# CY8C4xxx register map
File version: 0.1
Registers are 8-bit, read-write, no defined reset value unless marked. A register's access mark holds for its fields unless they carry their own. Offsets are from the block's base; [hi:lo] are bit positions; {n}, {i} and the like mark numbered series.

## CLK — Programmable clocks
Base 0x40020000
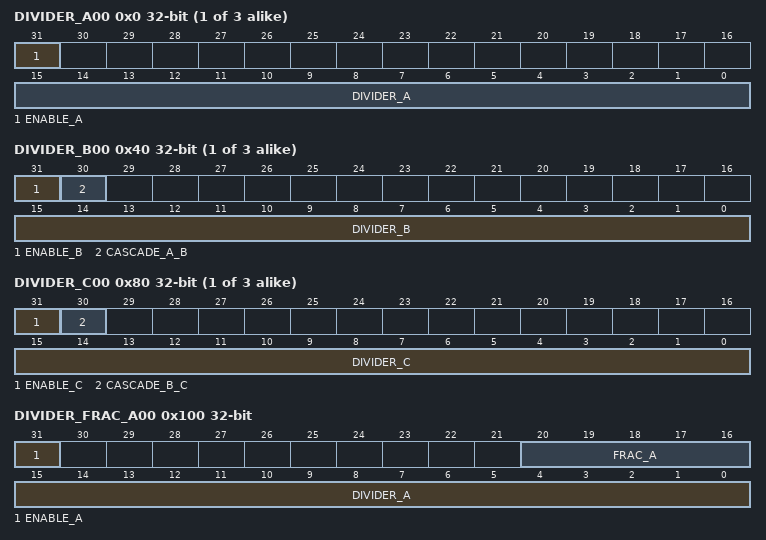
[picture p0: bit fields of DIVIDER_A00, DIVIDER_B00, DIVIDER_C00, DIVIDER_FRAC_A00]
{0x0+4i} DIVIDER_A{i:02} 32-bit (i=0..2) — Clock Divider Configuration
  [31] ENABLE_A — Enable divider A.
  [15:0] DIVIDER_A — Divider value for divider A in the row. OUTPUT= INPUT / (DIVIDER_A+1). In other words, a value of 0 means divide by 1. Note that selecting divide by 1 (value 0) does not work for blocks that require full DIVIDED_CLOCK clock reconstruction (See Section 20.6 in SAS).
{0x40+4i} DIVIDER_B{i:02} 32-bit (i=0..2) — Clock Divider Configuration
  [31] ENABLE_B — Enable divider B.
  [30] CASCADE_A_B — Cascade divider A into divider B
  [15:0] DIVIDER_B — Divider value for divider B in the row. OUTPUT= INPUT / (DIVIDER_B+1). In other words, a value of 0 means divide by 1. Note that selecting divide by 1 (value 0) does not work for blocks that require full DIVIDED_CLOCK clock reconstruction (See Section 20.6 in SAS). Also note that dividide by 1 does not work if CASCADE_A_B=1.
{0x80+4i} DIVIDER_C{i:02} 32-bit (i=0..2) — Clock Divider Configuration
  [31] ENABLE_C — Enable divider C.
  [30] CASCADE_B_C — Cascade divider B into divider C
  [15:0] DIVIDER_C — Divider value for divider C in the row. OUTPUT= INPUT / (DIVIDER_C+1). In other words, a value of 0 means divide by 1. Note that selecting divide by 1 (value 0) does not work for blocks that require full DIVIDED_CLOCK clock reconstruction (See Section 20.6 in SAS). Also note that dividide by 1 does not work if CASCADE_A_B=1.
0x100 DIVIDER_FRAC_A00 32-bit — Frac Divider Configuration
  [31] ENABLE_A — Enable divider A.
  [20:16] FRAC_A — Fractional divider value: 0/32 .. 31/32
  [15:0] DIVIDER_A — Divider value for divider A in the row. OUTPUT= INPUT / (DIVIDER_A+1). In other words, a value of 0 means divide by 1. Note that selecting divide by 1 (value 0) does not work for blocks that require full DIVIDED_CLOCK clock reconstruction (See Section 20.6 in SAS).
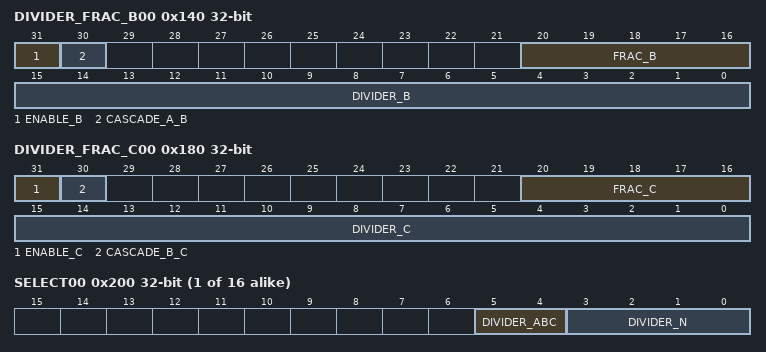
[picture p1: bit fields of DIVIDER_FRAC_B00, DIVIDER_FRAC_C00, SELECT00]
0x140 DIVIDER_FRAC_B00 32-bit — Frac Divider Configuration
  [31] ENABLE_B — Enable divider B.
  [30] CASCADE_A_B — Cascade divider A into divider B
  [20:16] FRAC_B — Fractional divider value: 0/32 .. 31/32
  [15:0] DIVIDER_B — Divider value for divider B in the row. OUTPUT= INPUT / (DIVIDER_B+1). In other words, a value of 0 means divide by 1. Note that selecting divide by 1 (value 0) does not work for blocks that require full DIVIDED_CLOCK clock reconstruction (See Section 20.6 in SAS). Also note that dividide by 1 does not work if CASCADE_A_B=1.
0x180 DIVIDER_FRAC_C00 32-bit — Frac Divider Configuration
  [31] ENABLE_C — Enable divider C.
  [30] CASCADE_B_C — Cascade divider B into divider C
  [20:16] FRAC_C — Fractional divider value: 0/32 .. 31/32
  [15:0] DIVIDER_C — Divider value for divider C in the row. OUTPUT= INPUT / (DIVIDER_C+1). In other words, a value of 0 means divide by 1. Note that selecting divide by 1 (value 0) does not work for blocks that require full DIVIDED_CLOCK clock reconstruction (See Section 20.6 in SAS). Also note that dividide by 1 does not work if CASCADE_A_B=1.
{0x200+4i} SELECT{i:02} 32-bit (i=0..15) — Clock Routing Configuration
  [5:4] DIVIDER_ABC — Select which divider from row to use.
    0=OFF; 1=A; 2=B; 3=C
  [3:0] DIVIDER_N — Select divider bank row to source clock from. ?Addressed as following:?0 to NUMDIV-1: Non-fractional divider?NUMDIV to NUMFRACDIV: Fractional divider?E.g. PSOC4A NUMDIV=3, NUMFRACDIV=1?0 to 2: non-fractional divider 0 to 2?3: fractional divider 0

## PRT0 — GPIO Port Registers
Base 0x40040000
Same registers: PRT1 0x40040100, PRT2 0x40040200, PRT3 0x40040300, PRT4 0x40040400
0x00 DR 32-bit — Port Output Data Register
  [7:0] DATAREG — The data written to this register specifies the high ('1') or low ('0') state for a specific pin. One bit is used for each pin: bit 0 pin 0, bit 1 pin 1, ?, bit 7 for pin 7.
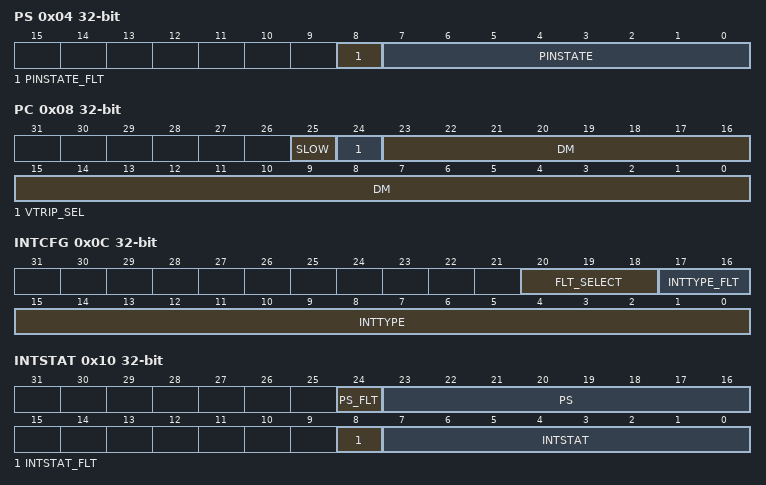
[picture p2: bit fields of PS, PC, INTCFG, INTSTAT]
0x04 PS 32-bit — Port Pin State Register
  [8] PINSTATE_FLT ro — Reads of this register return the logical state of the filtered pin.
  [7:0] PINSTATE ro — Reads of this register return the logical state of the corresponding I/O pin. The data read from this register specifies the logical state of the pin:?1: Reads HIGH if the pin voltage is above the input buffer threshold, logic high.?0: Reads LOW if the pin voltage is below that threshold, logic low.?If the drive mode for the pin is set to high Z Analog, the pin state will read 0 independent of the voltage on the pin.
0x08 PC 32-bit — Port Configuration Register
  [25] SLOW — This bit controls the output edge rate of all pins on the port:?0: fast.?1: slow.
  [24] VTRIP_SEL — The GPIO cells include a VTRIP_SEL signal to alter the input buffer voltage. Note: this bit is ignored for SIO ports, the VTRIP_SEL settings in the SIO register are used instead (a separate VTRIP_SEL is provided for each pin pair).
  [23:0] DM — The GPIO drive mode for a specific pin. Three bits are used for each pin: bits 0, 1 and 2 for pin 0, bits 3, 4 and 5 for pin 1, ?, bits 21, 22 and 23 for pin 7.?Note: when initializing IO's that are connected to a live bus (such as I2C), make sure the IO-Matrix is properly configured (HSIOM_PRT_SELx) before turning the IO on here to avoid producing glitches on the bus.
    0=OFF; 1=INPUT; 2=Cy0_PU; 3=PD_1; 4=Cy0_Z; 5=Z_1; 6=Cy0_1; 7=PD_PU
0x0C INTCFG 32-bit — Port IRQ Configuration Register
  [20:18] FLT_SELECT — Selects which pin is routed through the 50ns glitch filter to provide a glitch-safe interrupt.
  [17:16] INTTYPE_FLT — Same for the glitch filtered pin (selected by FLT_SELECT).
    0=DISABLE; 1=RISING; 2=FALLING; 3=BOTH
  [15:0] INTTYPE — Sets which edge will trigger an IRQ for a specific pin. Two bits are used for each pin: bits 0 and 1 for pin 0, bits 2 and 3 for pin 1, ?, bits 14 and 15 for pin 7.
    0=DISABLE; 1=RISING; 2=FALLING; 3=BOTH
0x10 INTSTAT 32-bit — Port IRQ Status Register
  [24] PS_FLT ro — This is a duplicate of the contents of the PS register, provided here to allow reading of both pin state and interrupt state of the port in a single read operation.
  [23:16] PS ro — This is a duplicate of the contents of the PS register, provided here to allow reading of both pin state and interrupt state of the port in a single read operation.
  [8] INTSTAT_FLT write-once — Deglitched interrupt pending (selected by FLT_SELECT).
  [7:0] INTSTAT write-once — Bit n indicates interrupt pending on pin #n. Firmware writes 1 to clear the interrupt.
0x18 PC2 32-bit — Port Secondary Configuration Register
  [7:0] INP_DIS — Disables the input buffer indepent of the port control drive mode (PC.DM). This bit should be set when analog signals are present on the pin and PC.DM != 0 is required to use the output driver.
